# CONTROLSS_G2_EPWM11_CONTROLSS_G2_EPWM11 register map
Vendor: Texas Instruments
Peripheral module from a debugger description file (folder AM263).
Registers are 16-bit, read-write, reset values left out (the file's numbers can be read two ways) unless marked. A register's access mark holds for its fields unless they carry their own. Offsets are as the file gives them; lines under a group give offsets from that group; [hi:lo] are bit positions; {n}, {i} and the like mark numbered series; 'fields as' and 'values as' point back to an identical list; <NAME> marks a mode.

## CONTROLSS_G2_EPWM11_CONTROLSS_G2_EPWM11 (part 1 of 4)
0x12A CONTROLSS_G2_EPWM11_TZOSTFLG ro
  [15:0] DCCAP — Digital Compare Time-Base Counter Capture To enable time-base counter capture, set the DCCAPCLT[CAPE] bit to 1. If enabled, reflects the value of the time-base counter (TBCTR) on the low to high edge transition of a filtered (DCEVTFLT) event. Further capture events are ignored until the next period or zero as selected by the DCFCTL[PULSESEL] bit. Shadowing of DCCAP is enabled and disabled by the DCCAPCTL[SHDWMODE] bit. By default this register is shadowed. - If DCCAPCTL[SHDWMODE] = 0, then the shadow is enabled. In this mode, the active register is copied to the shadow register on the TBCTR = TBPRD or TBCTR = zero as defined by the DCFCTL[PULSESEL] bit. CPU reads of this register will return the shadow register value. - If DCCAPCTL[SHDWMODE] = 1, then the shadow register is disabled. In this mode, CPU reads will return the active register value. The active and shadow registers share the same memory map address.
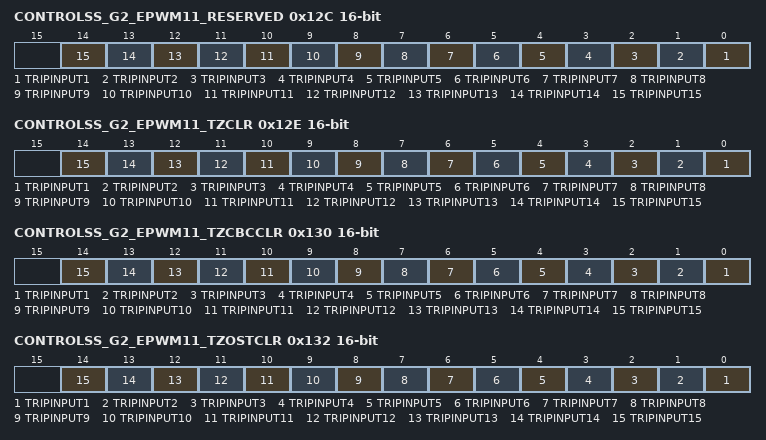
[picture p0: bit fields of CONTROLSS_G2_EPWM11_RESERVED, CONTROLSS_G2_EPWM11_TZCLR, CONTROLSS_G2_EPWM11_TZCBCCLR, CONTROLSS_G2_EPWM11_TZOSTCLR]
0x12C CONTROLSS_G2_EPWM11_RESERVED
  [n-1] TRIPINPUT{n} (n=1..15) — TRIP Input {n} 0: Trip Input {n} not selected as combinational ORed input 1: Trip Input {n} selected as combinational ORed input to DCAH mux
0x12E CONTROLSS_G2_EPWM11_TZCLR
  [n-1] TRIPINPUT{n} (n=1..15) — TRIP Input {n} 0: Trip Input {n} not selected as combinational ORed input 1: Trip Input {n} selected as combinational ORed input to DCAL mux
0x130 CONTROLSS_G2_EPWM11_TZCBCCLR
  [n-1] TRIPINPUT{n} (n=1..15) — TRIP Input {n} 0: Trip Input {n} not selected as combinational ORed input 1: Trip Input {n} selected as combinational ORed input to DCBH mux
0x132 CONTROLSS_G2_EPWM11_TZOSTCLR
  fields as CONTROLSS_G2_EPWM11_TZCLR
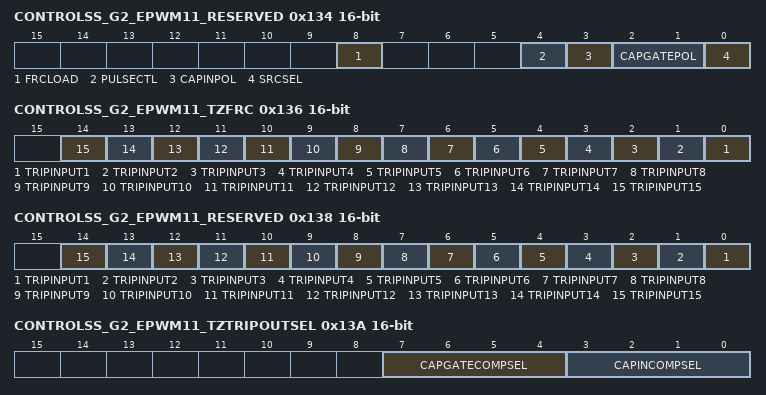
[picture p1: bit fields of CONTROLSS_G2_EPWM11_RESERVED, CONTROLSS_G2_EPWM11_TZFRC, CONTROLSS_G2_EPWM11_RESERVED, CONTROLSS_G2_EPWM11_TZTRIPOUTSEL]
0x134 CONTROLSS_G2_EPWM11_RESERVED access not given
  [8] FRCLOAD — 0: Writing of 0 is ignored. Always reads back a 0. 1: Forces a LOAD to occur on the DCCAP - an equivalent LOAD.active pulse (access RW RRETURNS0S)
  [4] PULSECTL rw — Capture Input Polarity Select Mux: 0: Pulse selection determined by PULSESEL bits (common pulse selection for Blanking and Capture logic) 1: Pulse selection determined by CAPMIXSEL register (independent pulse selection for Blaning and Capture logic)
  [3] CAPINPOL rw — Capture Input Polarity Select Mux: 0: CAPIN.sync not inverted 1: CAPIN.sync Inverted Default state assumption for these inputs can be active high. If the user is providing active low signal then invert option can be configured
  [2:1] CAPGATEPOL rw — Capture Gate Input Polarity Select Mux: 00: Set to 1 - Gate is always ON 01: Set to 0 - Gate is always OFF 10: CAPGATE.sync 11: CAPGATE.sync Inverted Default state assumption for these inputs can be active high. If the user is providing active low signal then invert option can be configured
  [0] SRCSEL rw — Capture Logic Input Select Mux: 0: DCEVTFILT (Sync) - same as Type-4 1: CAPIN.sync
0x136 CONTROLSS_G2_EPWM11_TZFRC
  [n-1] TRIPINPUT{n} (n=1..15) — TRIP Input {n} 0: Trip Input {n} not selected as combinational ORed input 1: Trip Input {n} selected as combinational ORed input to CAPGATE mux
0x138 CONTROLSS_G2_EPWM11_RESERVED
  [n-1] TRIPINPUT{n} (n=1..15) — TRIP Input {n} 0: Trip Input {n} not selected as combinational ORed input 1: Trip Input {n} selected as combinational ORed input to CAPIN mux
0x13A CONTROLSS_G2_EPWM11_TZTRIPOUTSEL
  [7:4] CAPGATECOMPSEL — Digital Compare A Low Input Select Bits 0000: TRIPIN1 0001: TRIPIN2 0010: TRIPIN3 0011: TRIPIN4 ... 1011: TRIPIN12 1100: Reserved 1101: TRIPIN14 1110: TRIPIN15 1111: Trip combination input (all trip inputs selected by CAPGATETRIPSEL register ORed together)
  [3:0] CAPINCOMPSEL — Digital Compare A High Input Select Bits 0000: TRIPIN1 0001: TRIPIN2 0010: TRIPIN3 0011: TRIPIN4 ... 1011: TRIPIN12 1100: Reserved 1101: TRIPIN14 1110: TRIPIN15 1111: Trip combination input (all trip inputs selected by CAPINTRIPSEL register ORed together)
0x13C CONTROLSS_G2_EPWM11_RESERVED
  [7:0] SPARE1_BITS — Not used in design currently
0x148 CONTROLSS_G2_EPWM11_ETSEL
  [7:0] SPARE2_BITS — Not used in design currently
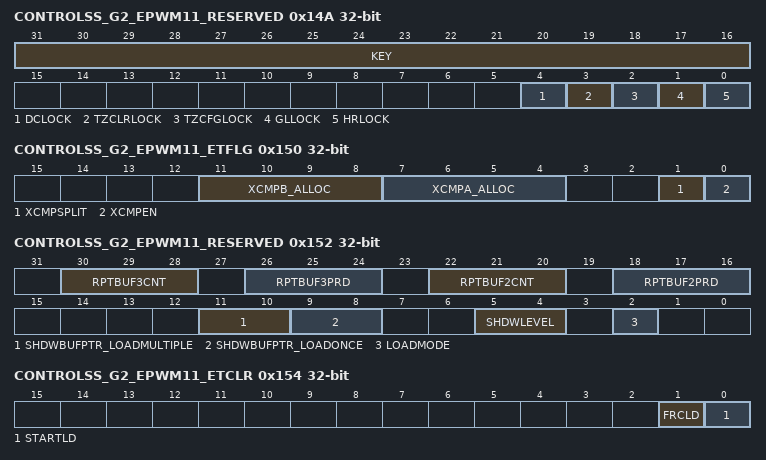
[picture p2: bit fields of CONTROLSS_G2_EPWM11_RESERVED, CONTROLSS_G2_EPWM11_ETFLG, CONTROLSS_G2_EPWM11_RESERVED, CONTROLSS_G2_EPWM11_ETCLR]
0x14A CONTROLSS_G2_EPWM11_RESERVED 32-bit access not given
  [31:16] KEY — Write to this register succeeds only if this field is written with a value of 0xa5a5 Note: [1] Due to this KEY, only 32-bit writes will succeed (provided the KEY matches). 16-bit writes to the upper or lower half of this register will be ignored (access RW RRETURNS0S)
  [4] DCLOCK — 0:Digital Compare registers from 0xC0 to 0xD9 offsets are protected by EALLOW. 1: Digital Compare registers from 0xC0 and 0xD9 offsets are locked and not writable. (access RWONCE WONCE)
  [3] TZCLRLOCK — 0:Digital Compare registers from 0x97 to 0x9B offsets are protected by EALLOW. 1: Digital Compare registers from 0x97 and 0x9B offsets are locked and not writable. (access RWONCE WONCE)
  [2] TZCFGLOCK — 0:TripZone registers from 0x80 to 0x8D and TZTRIPOUTSEL at 0x9D offsets are protected by EALLOW. 1: TripZone registers from 0x80 and 0x8D and TZTRIPOUTSEL at 0x9D offsets are locked and not writable. (access RWONCE WONCE)
  [1] GLLOCK — 0:TripZone registers from 0x34 to 0x35 offsets are protected by EALLOW. 1: TripZone registers from 0x34 to 0x35 offsets are locked and not writable (access RWONCE WONCE)
  [0] HRLOCK — 0: HRPWM registers from 0x20 to 0x2D offsets are protected by EALLOW 1: HRPWM registers from 0x20 and 0x2D offsets are locked and not writable. (access RWONCE WONCE)
0x14C CONTROLSS_G2_EPWM11_ETPS ro
  [15:0] HWVDELVAL — Hardware Valley Delay Value Register This read only register reflects the hardware delay value calculated by the equations defined in VCAPCTL[VDELAYDIV]. This reflects the latest value from the hardware calculations and can change every time valley capture sequence is triggered and VCAP1 and VCAP2 values are updated.
0x14E CONTROLSS_G2_EPWM11_RESERVED ro
  [15:0] VCNTVAL — Valley Time Base Counter Register This register reflects the captured VCNT value upon occurrence of STOPEDGE selected in VCNTCFG register.
0x150 CONTROLSS_G2_EPWM11_ETFLG 32-bit
  [11:8] XCMPB_ALLOC — XCMPn register allocation for CMPB: - 0 --' Reserved - 1 --' Reserved - 2 --' Reserved - 3 --' Reserved - 4 --' Reserved - 5 --' XCMP5 - 6 --' XCMP5, XCMP6 - 7 --' XCMP5, XCMP6, XCMP7 - 8 --' XCMP5, XCMP6, XCMP7, XCMP8 This register settings will take effect only when XCMPEN==1 And XCMPSPLIT ==1
  [7:4] XCMPA_ALLOC — XCMPn register allocation for CMPA: - 0 --' No XCMP - 1 --' XCMP1 - 2 --' XCMP1, XCMP2 - 3 --' XCMP1, XCMP2, XCMP3 - 4 --' XCMP1, XCMP2, XCMP3, XCMP4 - 5 --' XCMP1, XCMP2, XCMP3, XCMP4, XCMP5 - 6 --' XCMP1, XCMP2, XCMP3, XCMP4, XCMP5, XCMP6 - 7 --' XCMP1, XCMP2, XCMP3, XCMP4, XCMP5, XCMP6, XCMP7 - 8 --' XCMP1, XCMP2, XCMP3, XCMP4, XCMP5, XCMP6, XCMP7, XCMP8 This register settings will take effect only when XCMPEN==1 If XCMPSPLIT ==1, this field cannot be greater than 4. If XCMPSPLIT ==1 only lower 3 bits are used in this field.
  [1] XCMPSPLIT — XCMP Register Allocation Options: 0 : XCMP1-8 --' CMPA 1 : XCMP1-4 --'CMPA, XCMP5-8 ? CMPB This register settings will take effect only when XCMPEN==1
  [0] XCMPEN — XCMP Compare Register Operation Enable: 0 XCMP register operation Disabled (operation compatible to Type-4) 1 XCMP register operation Enabled (New CMPx registers are effective - section 1.3 details the operation)
0x152 CONTROLSS_G2_EPWM11_RESERVED 32-bit access per field
  [30:28] RPTBUF3CNT ro — Repeat Count Status Shadow Buffer 3: These bits indicate how many times shadow buffer 3 has been be applied before moving to the next buffer I,e, shadow buffer 1. 0,0,0 Shadow buffer reset value with STARTLD and copied to Active register 0,0,1 Shadow buffer applied twice on 2 successive load strobes 0,1,0 Shadow buffer applied thrice on 3 successive load strobes . . 1,1,1 Shadow buffer applied 8 times on 8 successive load strobes These bits reset to zero every time STARTLD is initiated. More details in section 1.3.3
  [26:24] RPTBUF3PRD rw — Repeat Count Shadow Buffer 3 : These bits indicate how many times shadow buffer 3 will be applied before moving to the next buffer I,e, shadow buffer 1. 0,0,0 Apply shadow buffer once and move to the next shadow buffer on the following load pulse 0,0,1 Apply shadow buffer twice on 2 successive load strobes and move to the next shadow buffer on the following load pulse 0,1,0 Apply shadow buffer thrice on 3 successive load strobes and move to the next shadow buffer on the following load pulse . . 1,1,1 Apply shadow buffer 8 times on 8 successive load strobes and move to the next shadow buffer on the following load pulse More details in section 1.3.3
  [22:20] RPTBUF2CNT ro — Repeat Count Status Shadow Buffer 2: These bits indicate how many times shadow buffer 2 has been be applied before moving to the next buffer I,e, shadow buffer 1. 0,0,0 Shadow buffer reset value with STARTLD and copied to Active register 0,0,1 Shadow buffer applied twice on 2 successive load strobes 0,1,0 Shadow buffer applied thrice on 3 successive load strobes . . 1,1,1 Shadow buffer applied 8 times on 8 successive load strobes These bits reset to zero every time STARTLD is initiated.
  [18:16] RPTBUF2PRD rw — Repeat Count Shadow Buffer 2 : These bits indicate how many times shadow buffer 2 will be applied before moving to the next buffer I,e, shadow buffer 1. 0,0,0 Apply shadow buffer once and move to the next shadow buffer on the following load pulse 0,0,1 Apply shadow buffer twice on 2 successive load strobes and move to the next shadow buffer on the following load pulse 0,1,0 Apply shadow buffer thrice on 3 successive load strobes and move to the next shadow buffer on the following load pulse . . 1,1,1 Apply shadow buffer 8 times on 8 successive load strobes and move to the next shadow buffer on the following load pulse More details in section 1.3.3
  [11:10] SHDWBUFPTR_LOADMULTIPLE ro — Register Load event count: These bits indicate the current shadow buffer in use. 0,0 Reset value 0,1 1 Shadow buffer 1 in use 1,0 2 Shadow buffer 2 in use 1,1 3 Shadow buffer 3 in use More details in section 1.3.3
  [9:8] SHDWBUFPTR_LOADONCE rw — Register Load event count: These bits indicate the current shadow buffer in use. 0,0 Reset value 0,1 1 Shadow buffer 1 in use 1,0 2 Shadow buffer 2 in use 1,1 3 Shadow buffer 3 in use More details in section 1.3.3
  [5:4] SHDWLEVEL rw — Shadow Register Level Allocation Options: These bits are effective only when XCMPEN is enabled. 0,0 : XXXX Shadow level is set at zero. XXXX Active register is available 0,1 : XXXX Shadow level is set at 1. XXXX_SHDW1 and Active registers are available 1,0 : XXXX Shadow level is set at 1. XXXX_SHDW1, XXXX_SHDW2 and Active registers are available 1,1 : XXXX Shadow level is set at 1. XXXX_SHDW1, XXXX_SHDW2, XXXX_SHDW3 and Active registers are available
  [2] LOADMODE rw — Load mode selection for Shadow registers: These bits are effective only when XCMPEN is enabled. 0 : (LOADONCE) Load occurs at every load strobe (CNT_Zero or FRCLD) from SHDWn? Active registers. And STARTLD is cleared after 1 load strobe. SHDWBUFPTR is not automatically decremented in this case. User would set the SHDWBUFPTR for subsequent loads. 1 : (LOADMULTIPLE) Load occurs at every load strobe (CNT_Zero or FRCLD) from SHDWn?Active registers. And STARTLD is cleared after SHDWLEVEL number of load strobes. SHDWBUFPTR decrements by 1 on a load strobe, until the SHDWBUFPTR reaches 1. More details in section 1.3.3
0x154 CONTROLSS_G2_EPWM11_ETCLR 32-bit access not given
  [1] FRCLD — Force reload event in one shot mode : Writing a 1 to this bit turn force one load event at the input of the event pre-scale counter as shown in the diagram below. This bit is intended to be used for testing and/or software force loading of the events in global load mode. Writing of 0 will be ignored. Always reads back a 0. (access RW RRETURNS0S)
  [0] STARTLD — Enable reload event : Writing a 1 to this bit turn the one shot latch condition ON. Upon occurrence of a chosen load strobe, one shadow to active reload occurs and the latch will be cleared. Hence writing '1' to this bit would allow load strobe event to pass through and block further strobe events. Writing of 0 will be ignored. Always reads back a 0. (access RW RRETURNS0S)
0x156 CONTROLSS_G2_EPWM11_RESERVED 32-bit
  [4:0] XLOADLINK — XLOAD Link Bits: Writes to the XLOAD registers in the ePWM module selected by the following bit selections results in a simultaneous write to the current ePWM module's XLOAD registers 00000: ePWM1 00001: ePWM2 00010: ePWM3 00011: ePWM4 00100: ePWM5 00101: ePWM6 00110: ePWM7 00111: ePWM8 01000: ePWM9 01001: ePWM10 01010: ePWM11 01011: ePWM12 01100: ePWM13 ... 11111: ePWM32
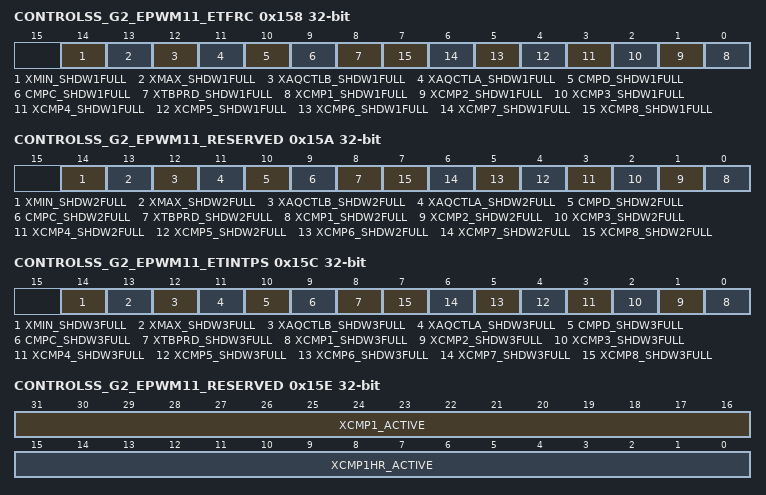
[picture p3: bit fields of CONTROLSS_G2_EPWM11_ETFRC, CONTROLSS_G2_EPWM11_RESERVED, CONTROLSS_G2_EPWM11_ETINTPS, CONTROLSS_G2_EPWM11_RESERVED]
0x158 CONTROLSS_G2_EPWM11_ETFRC 32-bit ro
  [14] XMIN_SHDW1FULL — 0 Shadow Register is not full yet 1 Indicates the Shadow Register is full, a CPU write will over-write current Shadow value
  [13] XMAX_SHDW1FULL — 0 Shadow Register is not full yet 1 Indicates the Shadow Register is full, a CPU write will over-write current Shadow value
  [12] XAQCTLB_SHDW1FULL — 0 Shadow Register is not full yet 1 Indicates the Shadow Register is full, a CPU write will over-write current Shadow value
  [11] XAQCTLA_SHDW1FULL — 0 Shadow Register is not full yet 1 Indicates the Shadow Register is full, a CPU write will over-write current Shadow value
  [10] CMPD_SHDW1FULL — 0 Shadow Register is not full yet 1 Indicates the Shadow Register is full, a CPU write will over-write current Shadow value
  [9] CMPC_SHDW1FULL — 0 Shadow Register is not full yet 1 Indicates the Shadow Register is full, a CPU write will over-write current Shadow value
  [8] XTBPRD_SHDW1FULL — 0 Shadow Register is not full yet 1 Indicates the Shadow Register is full, a CPU write will over-write current Shadow value
  [n-1] XCMP{n}_SHDW1FULL (n=1..8) — 0 Shadow Register is not full yet 1 Indicates the Shadow Register is full, a CPU write will over-write current Shadow value
0x15A CONTROLSS_G2_EPWM11_RESERVED 32-bit ro
  [14] XMIN_SHDW2FULL — 0 Shadow Register is not full yet 1 Indicates the Shadow Register is full, a CPU write will over-write current Shadow value
  [13] XMAX_SHDW2FULL — 0 Shadow Register is not full yet 1 Indicates the Shadow Register is full, a CPU write will over-write current Shadow value
  [12] XAQCTLB_SHDW2FULL — 0 Shadow Register is not full yet 1 Indicates the Shadow Register is full, a CPU write will over-write current Shadow value
  [11] XAQCTLA_SHDW2FULL — 0 Shadow Register is not full yet 1 Indicates the Shadow Register is full, a CPU write will over-write current Shadow value
  [10] CMPD_SHDW2FULL — 0 Shadow Register is not full yet 1 Indicates the Shadow Register is full, a CPU write will over-write current Shadow value
  [9] CMPC_SHDW2FULL — 0 Shadow Register is not full yet 1 Indicates the Shadow Register is full, a CPU write will over-write current Shadow value
  [8] XTBPRD_SHDW2FULL — 0 Shadow Register is not full yet 1 Indicates the Shadow Register is full, a CPU write will over-write current Shadow value
  [n-1] XCMP{n}_SHDW2FULL (n=1..8) — 0 Shadow Register is not full yet 1 Indicates the Shadow Register is full, a CPU write will over-write current Shadow value
0x15C CONTROLSS_G2_EPWM11_ETINTPS 32-bit ro
  [14] XMIN_SHDW3FULL — 0 Shadow Register is not full yet 1 Indicates the Shadow Register is full, a CPU write will over-write current Shadow value
  [13] XMAX_SHDW3FULL — 0 Shadow Register is not full yet 1 Indicates the Shadow Register is full, a CPU write will over-write current Shadow value
  [12] XAQCTLB_SHDW3FULL — 0 Shadow Register is not full yet 1 Indicates the Shadow Register is full, a CPU write will over-write current Shadow value
  [11] XAQCTLA_SHDW3FULL — 0 Shadow Register is not full yet 1 Indicates the Shadow Register is full, a CPU write will over-write current Shadow value
  [10] CMPD_SHDW3FULL — 0 Shadow Register is not full yet 1 Indicates the Shadow Register is full, a CPU write will over-write current Shadow value
  [9] CMPC_SHDW3FULL — 0 Shadow Register is not full yet 1 Indicates the Shadow Register is full, a CPU write will over-write current Shadow value
  [8] XTBPRD_SHDW3FULL — 0 Shadow Register is not full yet 1 Indicates the Shadow Register is full, a CPU write will over-write current Shadow value
  [n-1] XCMP{n}_SHDW3FULL (n=1..8) — 0 Shadow Register is not full yet 1 Indicates the Shadow Register is full, a CPU write will over-write current Shadow value
0x15E CONTROLSS_G2_EPWM11_RESERVED 32-bit
  [31:16] XCMP1_ACTIVE — XCMP1_ACTIVE Register The value in the XCMP1_ACTIVE register is loaded into CMPA/B (shadow/active) registers when shadow to active load occurs.
  [15:0] XCMP1HR_ACTIVE — XCMP1HR_ACTIVE Register The value in the XCMP1HR_ACTIVE register is loaded into CMPA/BHR (shadow/active) registers when shadow to active load occurs.
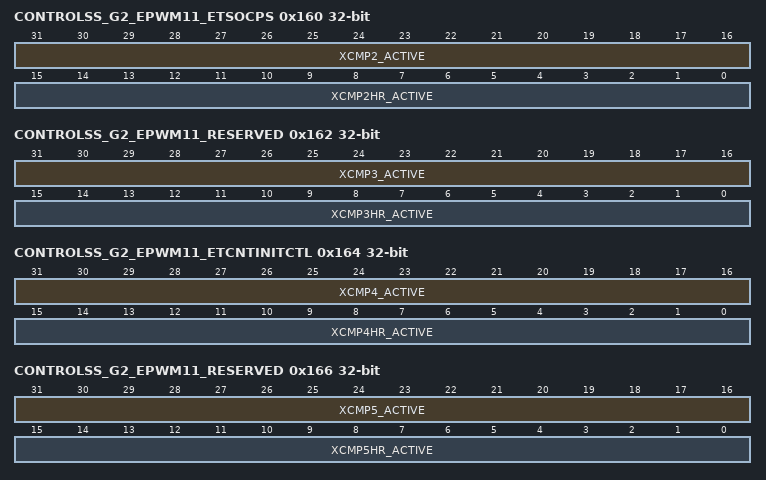
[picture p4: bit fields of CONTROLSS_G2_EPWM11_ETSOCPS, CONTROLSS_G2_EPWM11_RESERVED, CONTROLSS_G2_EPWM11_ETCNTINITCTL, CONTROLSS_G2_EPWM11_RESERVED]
0x160 CONTROLSS_G2_EPWM11_ETSOCPS 32-bit
  [31:16] XCMP2_ACTIVE — XCMP2_ACTIVE Register The value in the XCMP2_ACTIVE register is loaded into CMPA/B (shadow/active) registers when shadow to active load occurs.
  [15:0] XCMP2HR_ACTIVE — XCMP2HR_ACTIVE Register The value in the XCMP2HR_ACTIVE register is loaded into CMPA/BHR (shadow/active) registers when shadow to active load occurs.
0x162 CONTROLSS_G2_EPWM11_RESERVED 32-bit
  [31:16] XCMP3_ACTIVE — XCMP3_ACTIVE Register The value in the XCMP3_ACTIVE register is loaded into CMPA/B (shadow/active) registers when shadow to active load occurs.
  [15:0] XCMP3HR_ACTIVE — XCMP3HR_ACTIVE Register The value in the XCMP3HR_ACTIVE register is loaded into CMPA/BHR (shadow/active) registers when shadow to active load occurs.
0x164 CONTROLSS_G2_EPWM11_ETCNTINITCTL 32-bit
  [31:16] XCMP4_ACTIVE — XCMP4_ACTIVE Register The value in the XCMP4_ACTIVE register is loaded into CMPA/B (shadow/active) registers when shadow to active load occurs.
  [15:0] XCMP4HR_ACTIVE — XCMP4HR_ACTIVE Register The value in the XCMP4HR_ACTIVE register is loaded into CMPA/BHR (shadow/active) registers when shadow to active load occurs.
0x166 CONTROLSS_G2_EPWM11_RESERVED 32-bit
  [31:16] XCMP5_ACTIVE — XCMP5_ACTIVE Register The value in the XCMP5_ACTIVE register is loaded into CMPA/B (shadow/active) registers when shadow to active load occurs.
  [15:0] XCMP5HR_ACTIVE — XCMP5HR_ACTIVE Register The value in the XCMP5HR_ACTIVE register is loaded into CMPA/BHR (shadow/active) registers when shadow to active load occurs.
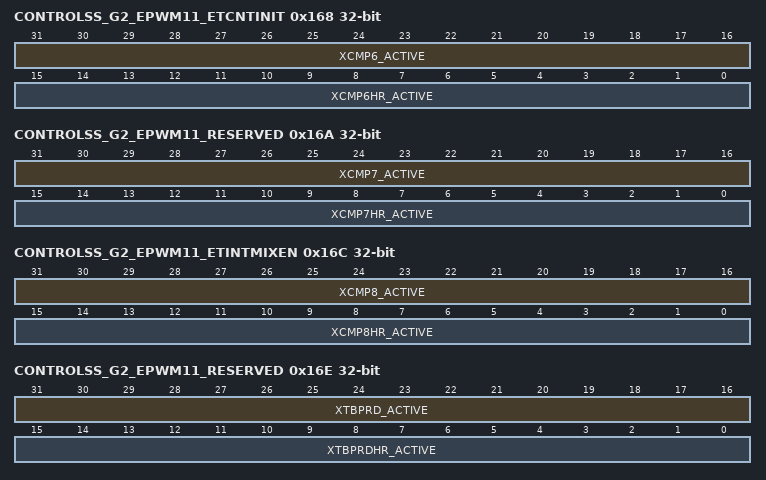
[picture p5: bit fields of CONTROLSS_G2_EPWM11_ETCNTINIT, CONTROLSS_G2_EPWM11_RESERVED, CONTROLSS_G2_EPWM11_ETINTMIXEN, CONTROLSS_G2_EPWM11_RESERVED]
0x168 CONTROLSS_G2_EPWM11_ETCNTINIT 32-bit
  [31:16] XCMP6_ACTIVE — XCMP6_ACTIVE Register The value in the XCMP6_ACTIVE register is loaded into CMPA/B (shadow/active) registers when shadow to active load occurs.
  [15:0] XCMP6HR_ACTIVE — XCMP6HR_ACTIVE Register The value in the XCMP6HR_ACTIVE register is loaded into CMPA/BHR (shadow/active) registers when shadow to active load occurs.
0x16A CONTROLSS_G2_EPWM11_RESERVED 32-bit
  [31:16] XCMP7_ACTIVE — XCMP7_ACTIVE Register The value in the XCMP7_ACTIVE register is loaded into CMPA/B (shadow/active) registers when shadow to active load occurs.
  [15:0] XCMP7HR_ACTIVE — XCMP7HR_ACTIVE Register The value in the XCMP7HR_ACTIVE register is loaded into CMPA/BHR (shadow/active) registers when shadow to active load occurs.
0x16C CONTROLSS_G2_EPWM11_ETINTMIXEN 32-bit
  [31:16] XCMP8_ACTIVE — XCMP8_ACTIVE Register The value in the XCMP8_ACTIVE register is loaded into CMPA/B (shadow/active) registers when shadow to active load occurs.
  [15:0] XCMP8HR_ACTIVE — XCMP8HR_ACTIVE Register The value in the XCMP8HR_ACTIVE register is loaded into CMPA/BHR (shadow/active) registers when shadow to active load occurs.
0x16E CONTROLSS_G2_EPWM11_RESERVED 32-bit
  [31:16] XTBPRD_ACTIVE — The value in the XTBPRD_ACTIVE register is loaded into TBPRD (shadow/active) registers when shadow to active load occurs.
  [15:0] XTBPRDHR_ACTIVE — The value in the XTBPRDHR_ACTIVE register is loaded into TBPRDHR (shadow/active) registers when shadow to active load occurs.
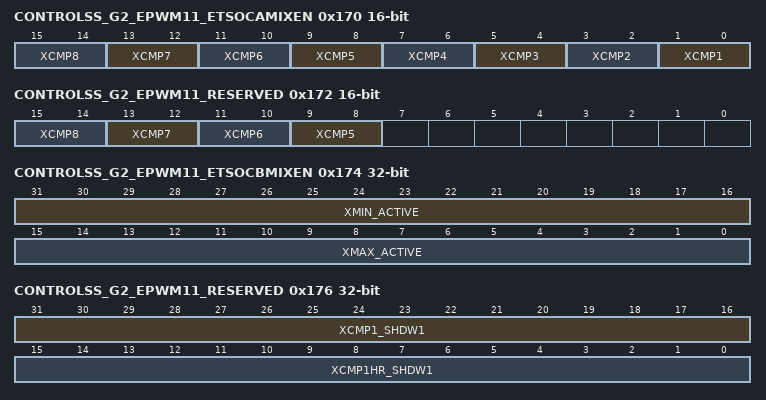
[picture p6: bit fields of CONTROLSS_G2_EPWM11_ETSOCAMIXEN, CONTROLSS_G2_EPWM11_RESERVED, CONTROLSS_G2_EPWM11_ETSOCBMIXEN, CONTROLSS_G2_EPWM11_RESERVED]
0x170 CONTROLSS_G2_EPWM11_ETSOCAMIXEN
  [2n-1:2n-2] XCMP{n} (n=1..8) — Action when Counter = CMP{n} 0,0 Do nothing (action disabled) 0,1 Clear (low) 1,0 Set (high) 1,1 Toggle (Low -' High, High -' Low)
0x172 CONTROLSS_G2_EPWM11_RESERVED
  [2n-1:2n-2] XCMP{n} (n=5..8) — Action when Counter = CMP{n} 0,0 Do nothing (action disabled) 0,1 Clear (low) 1,0 Set (high) 1,1 Toggle (Low -' High, High -' Low)
0x174 CONTROLSS_G2_EPWM11_ETSOCBMIXEN 32-bit
  [31:16] XMIN_ACTIVE — The value in the XMIN_ACTIVE register is used for comparision against the threshold of the capture counter at any given time.
  [15:0] XMAX_ACTIVE — The value in the XMAX_ACTIVE register is used for comparision against the threshold of the capture counter at any given time.
0x176 CONTROLSS_G2_EPWM11_RESERVED 32-bit
  [31:16] XCMP1_SHDW1 — XCMP1_SHDW1 Register The value in the XCMP1_SHDW1 register is loaded into XCMP1_ACTIVE register when shadow to active load occurs.
  [15:0] XCMP1HR_SHDW1 — XCMP1HR_SHDW1 Register The value in the XCMP1HR_SHDW1 register is loaded into XCMP1HR_ACTIVE register when shadow to active load occurs.
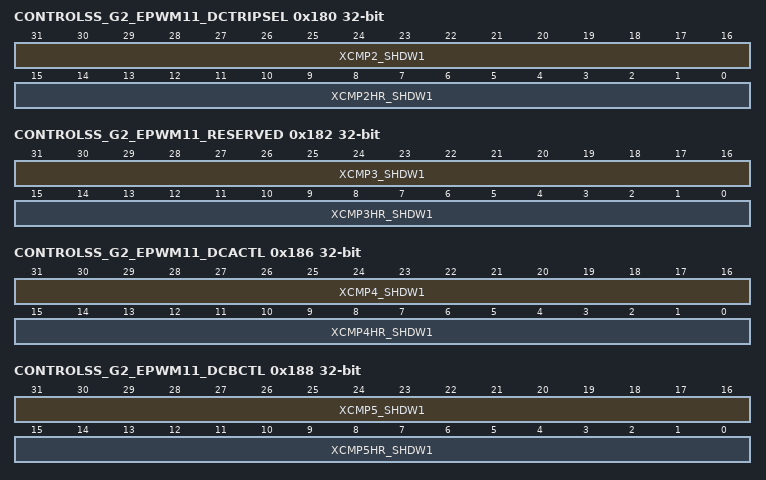
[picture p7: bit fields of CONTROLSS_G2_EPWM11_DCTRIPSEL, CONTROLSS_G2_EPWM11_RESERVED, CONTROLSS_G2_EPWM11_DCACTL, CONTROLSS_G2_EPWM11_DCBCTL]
0x180 CONTROLSS_G2_EPWM11_DCTRIPSEL 32-bit
  [31:16] XCMP2_SHDW1 — XCMP2_SHDW1 Register The value in the XCMP2_SHDW1 register is loaded into XCMP2_ACTIVE register when shadow to active load occurs.
  [15:0] XCMP2HR_SHDW1 — XCMP2HR_SHDW1 Register The value in the XCMP2HR_SHDW1 register is loaded into XCMP2HR_ACTIVE register when shadow to active load occurs.
0x182 CONTROLSS_G2_EPWM11_RESERVED 32-bit
  [31:16] XCMP3_SHDW1 — XCMP3_SHDW1 Register The value in the XCMP3_SHDW1 register is loaded into XCMP3_ACTIVE register when shadow to active load occurs.
  [15:0] XCMP3HR_SHDW1 — XCMP3HR_SHDW1 Register The value in the XCMP3HR_SHDW1 register is loaded into XCMP3HR_ACTIVE register when shadow to active load occurs.
0x186 CONTROLSS_G2_EPWM11_DCACTL 32-bit
  [31:16] XCMP4_SHDW1 — XCMP4_SHDW1 Register The value in the XCMP4_SHDW1 register is loaded into XCMP4_ACTIVE register when shadow to active load occurs.
  [15:0] XCMP4HR_SHDW1 — XCMP4HR_SHDW1 Register The value in the XCMP4HR_SHDW1 register is loaded into XCMP4HR_ACTIVE register when shadow to active load occurs.
0x188 CONTROLSS_G2_EPWM11_DCBCTL 32-bit
  [31:16] XCMP5_SHDW1 — XCMP5_SHDW1 Register The value in the XCMP5_SHDW1 register is loaded into XCMP5_ACTIVE register when shadow to active load occurs.
  [15:0] XCMP5HR_SHDW1 — XCMP5HR_SHDW1 Register The value in the XCMP5HR_SHDW1 register is loaded into XCMP5HR_ACTIVE register when shadow to active load occurs.
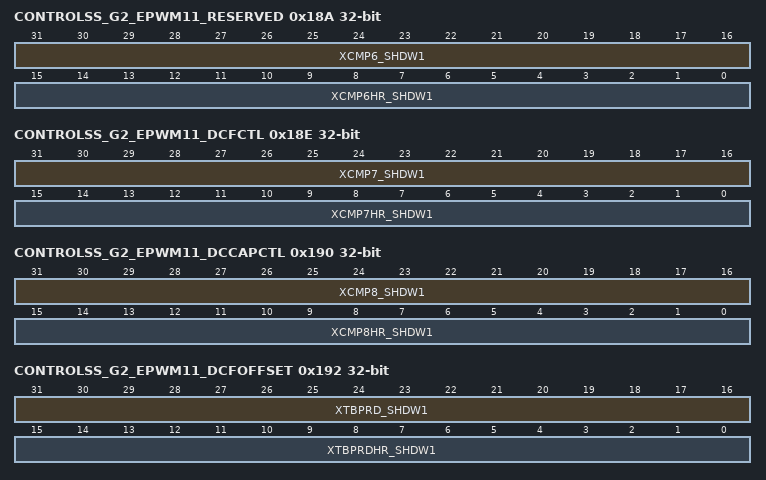
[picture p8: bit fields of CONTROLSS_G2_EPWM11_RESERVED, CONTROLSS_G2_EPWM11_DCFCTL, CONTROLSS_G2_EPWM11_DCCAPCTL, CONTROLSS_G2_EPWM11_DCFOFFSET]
0x18A CONTROLSS_G2_EPWM11_RESERVED 32-bit
  [31:16] XCMP6_SHDW1 — XCMP6_SHDW1 Register The value in the XCMP6_SHDW1 register is loaded into XCMP6_ACTIVE register when shadow to active load occurs.
  [15:0] XCMP6HR_SHDW1 — XCMP6HR_SHDW1 Register The value in the XCMP6HR_SHDW1 register is loaded into XCMP6HR_ACTIVE register when shadow to active load occurs.
0x18E CONTROLSS_G2_EPWM11_DCFCTL 32-bit
  [31:16] XCMP7_SHDW1 — XCMP7_SHDW1 Register The value in the XCMP7_SHDW1 register is loaded into XCMP7_ACTIVE register when shadow to active load occurs.
  [15:0] XCMP7HR_SHDW1 — XCMP7HR_SHDW1 Register The value in the XCMP7HR_SHDW1 register is loaded into XCMP7HR_ACTIVE register when shadow to active load occurs.
0x190 CONTROLSS_G2_EPWM11_DCCAPCTL 32-bit
  [31:16] XCMP8_SHDW1 — XCMP8_SHDW1 Register The value in the XCMP8_SHDW1 register is loaded into XCMP8_ACTIVE register when shadow to active load occurs.
  [15:0] XCMP8HR_SHDW1 — XCMP8HR_SHDW1 Register The value in the XCMP8HR_SHDW1 register is loaded into XCMP8HR_ACTIVE register when shadow to active load occurs.
0x192 CONTROLSS_G2_EPWM11_DCFOFFSET 32-bit
  [31:16] XTBPRD_SHDW1 — The value in the XTBPRD_SHDW1 register is loaded into XTBPRD_ ACTIVE register when shadow to active load occurs.
  [15:0] XTBPRDHR_SHDW1 — The value in the XTBPRDHR_SHDW1 register is loaded into XTBPRDHR_ACTIVE register when shadow to active load occurs.
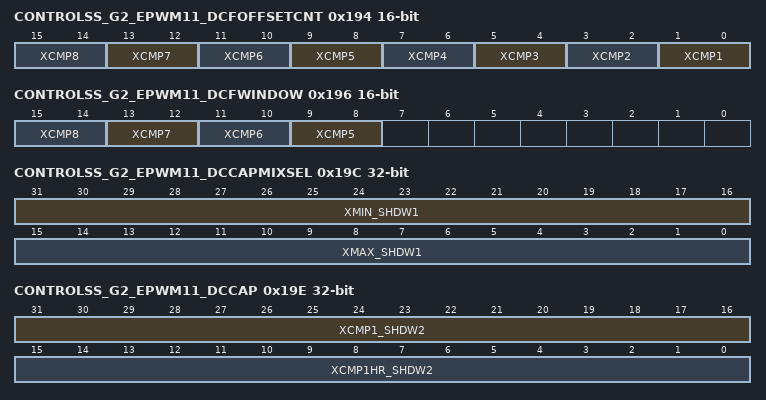
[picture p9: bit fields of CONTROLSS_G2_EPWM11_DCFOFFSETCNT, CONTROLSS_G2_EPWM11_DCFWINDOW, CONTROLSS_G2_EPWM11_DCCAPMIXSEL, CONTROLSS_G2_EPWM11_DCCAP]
0x194 CONTROLSS_G2_EPWM11_DCFOFFSETCNT
  fields as CONTROLSS_G2_EPWM11_ETSOCAMIXEN
0x196 CONTROLSS_G2_EPWM11_DCFWINDOW
  [2n-1:2n-2] XCMP{n} (n=5..8) — Action when Counter = CMP{n} 0,0 Do nothing (action disabled) 0,1 Clear (low) 1,0 Set (high) 1,1 Toggle (Low -' High, High -' Low)
0x198 CONTROLSS_G2_EPWM11_DCFWINDOWCNT
  [15:0] CMPC_SHDW1 — The value in the CMPC_SHDW1 register is loaded into CMPC_ACTIVE register when shadow to active load occurs.
0x19A CONTROLSS_G2_EPWM11_BLANKPULSEMIXSEL
  [15:0] CMPD_SHDW1 — The value in the CMPD_SHDW1 register is loaded into CMPD_ACTIVE register when shadow to active load occurs.
0x19C CONTROLSS_G2_EPWM11_DCCAPMIXSEL 32-bit
  [31:16] XMIN_SHDW1 — The value in the XMIN_SHDW1 register is loaded into XMIN_ACTIVE register when shadow to active load occurs.
  [15:0] XMAX_SHDW1 — The value in the XMAX_SHDW1 register is loaded into XMAX_ACTIVE register when shadow to active load occurs.
0x19E CONTROLSS_G2_EPWM11_DCCAP 32-bit
  [31:16] XCMP1_SHDW2 — XCMP1_SHDW2 Register The value in the XCMP1_SHDW2 register is loaded into XCMP1_ACTIVE register when shadow to active load occurs.
  [15:0] XCMP1HR_SHDW2 — XCMP1HR_SHDW2 Register The value in the XCMP1HR_SHDW2 register is loaded into XCMP1HR_ACTIVE register when shadow to active load occurs.
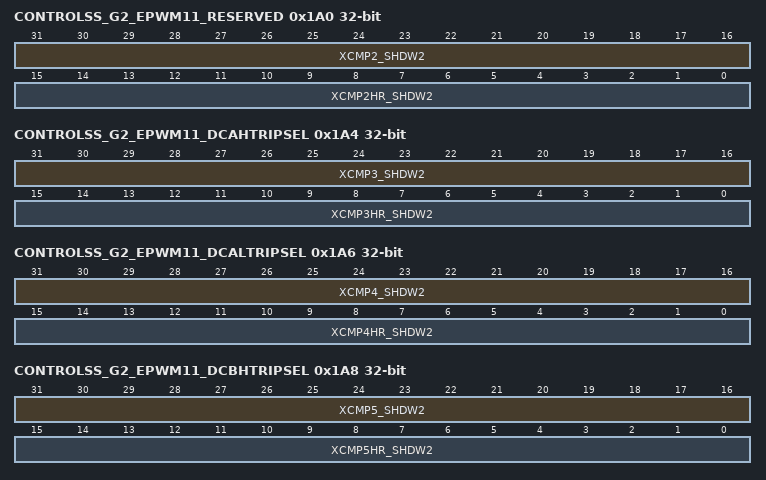
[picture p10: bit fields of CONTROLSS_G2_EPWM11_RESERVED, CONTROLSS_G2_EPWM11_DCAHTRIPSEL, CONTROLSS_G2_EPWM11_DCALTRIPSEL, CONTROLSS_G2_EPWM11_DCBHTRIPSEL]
0x1A0 CONTROLSS_G2_EPWM11_RESERVED 32-bit
  [31:16] XCMP2_SHDW2 — XCMP2_SHDW2 Register The value in the XCMP2_SHDW2 register is loaded into XCMP2_ACTIVE register when shadow to active load occurs.
  [15:0] XCMP2HR_SHDW2 — XCMP2HR_SHDW2 Register The value in the XCMP2HR_SHDW2 register is loaded into XCMP2HR_ACTIVE register when shadow to active load occurs.
0x1A4 CONTROLSS_G2_EPWM11_DCAHTRIPSEL 32-bit
  [31:16] XCMP3_SHDW2 — XCMP3_SHDW2 Register The value in the XCMP3_SHDW2 register is loaded into XCMP3_ACTIVE register when shadow to active load occurs.
  [15:0] XCMP3HR_SHDW2 — XCMP3HR_SHDW2 Register The value in the XCMP3HR_SHDW2 register is loaded into XCMP3HR_ACTIVE register when shadow to active load occurs.
0x1A6 CONTROLSS_G2_EPWM11_DCALTRIPSEL 32-bit
  [31:16] XCMP4_SHDW2 — XCMP4_SHDW2 Register The value in the XCMP4_SHDW2 register is loaded into XCMP4_ACTIVE register when shadow to active load occurs.
  [15:0] XCMP4HR_SHDW2 — XCMP4HR_SHDW2 Register The value in the XCMP4HR_SHDW2 register is loaded into XCMP4HR_ACTIVE register when shadow to active load occurs.
0x1A8 CONTROLSS_G2_EPWM11_DCBHTRIPSEL 32-bit
  [31:16] XCMP5_SHDW2 — XCMP5_SHDW2 Register The value in the XCMP5_SHDW2 register is loaded into XCMP5_ACTIVE register when shadow to active load occurs.
  [15:0] XCMP5HR_SHDW2 — XCMP5HR_SHDW2 Register The value in the XCMP5HR_SHDW2 register is loaded into XCMP5HR_ACTIVE register when shadow to active load occurs.
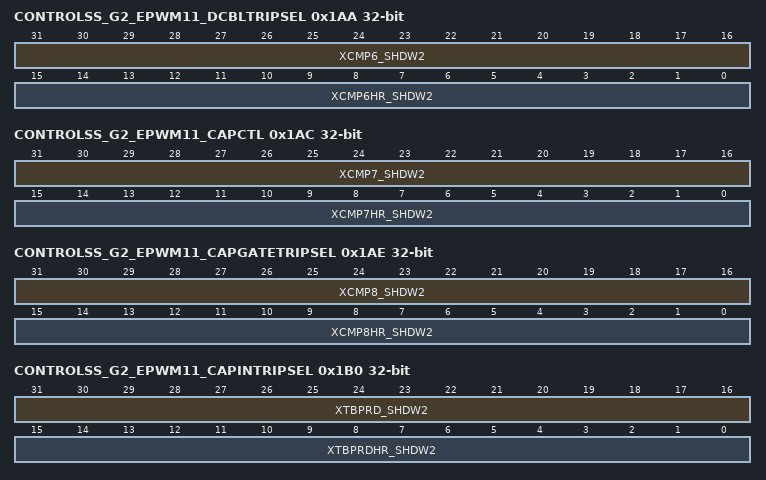
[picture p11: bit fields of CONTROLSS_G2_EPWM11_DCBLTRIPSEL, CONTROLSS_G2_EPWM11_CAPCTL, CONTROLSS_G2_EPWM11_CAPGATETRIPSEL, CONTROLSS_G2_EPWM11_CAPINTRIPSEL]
0x1AA CONTROLSS_G2_EPWM11_DCBLTRIPSEL 32-bit
  [31:16] XCMP6_SHDW2 — XCMP6_SHDW2 Register The value in the XCMP6_SHDW2 register is loaded into XCMP6_ACTIVE register when shadow to active load occurs.
  [15:0] XCMP6HR_SHDW2 — XCMP6HR_SHDW2 Register The value in the XCMP6HR_SHDW2 register is loaded into XCMP6HR_ACTIVE register when shadow to active load occurs.
0x1AC CONTROLSS_G2_EPWM11_CAPCTL 32-bit
  [31:16] XCMP7_SHDW2 — XCMP7_SHDW2 Register The value in the XCMP7_SHDW2 register is loaded into XCMP7_ACTIVE register when shadow to active load occurs.
  [15:0] XCMP7HR_SHDW2 — XCMP7HR_SHDW2 Register The value in the XCMP7HR_SHDW2 register is loaded into XCMP7HR_ACTIVE register when shadow to active load occurs.
0x1AE CONTROLSS_G2_EPWM11_CAPGATETRIPSEL 32-bit
  [31:16] XCMP8_SHDW2 — XCMP8_SHDW2 Register The value in the XCMP8_SHDW2 register is loaded into XCMP8_ACTIVE register when shadow to active load occurs.
  [15:0] XCMP8HR_SHDW2 — XCMP8HR_SHDW2 Register The value in the XCMP8HR_SHDW2 register is loaded into XCMP8HR_ACTIVE register when shadow to active load occurs.
0x1B0 CONTROLSS_G2_EPWM11_CAPINTRIPSEL 32-bit
  [31:16] XTBPRD_SHDW2 — The value in the XTBPRD_SHDW2 register is loaded into XTBPRD_ ACTIVE register when shadow to active load occurs.
  [15:0] XTBPRDHR_SHDW2 — The value in the XTBPRDHR_SHDW2 register is loaded into XTBPRDHR_ACTIVE register when shadow to active load occurs.
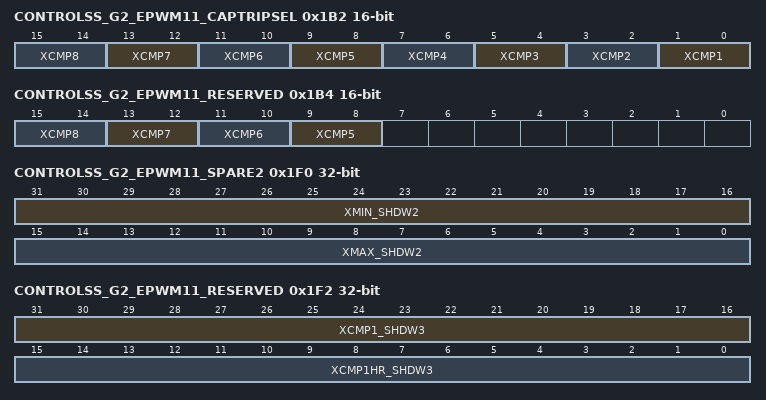
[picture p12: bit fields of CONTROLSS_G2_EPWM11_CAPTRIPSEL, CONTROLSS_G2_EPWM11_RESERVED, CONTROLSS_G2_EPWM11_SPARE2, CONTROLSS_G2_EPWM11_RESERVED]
0x1B2 CONTROLSS_G2_EPWM11_CAPTRIPSEL
  fields as CONTROLSS_G2_EPWM11_ETSOCAMIXEN
0x1B4 CONTROLSS_G2_EPWM11_RESERVED
  fields as CONTROLSS_G2_EPWM11_DCFWINDOW
0x1EC CONTROLSS_G2_EPWM11_SPARE1
  [15:0] CMPC_SHDW2 — The value in the CMPC_SHDW2 register is loaded into CMPC_ACTIVE register when shadow to active load occurs.
0x1EE CONTROLSS_G2_EPWM11_RESERVED
  [15:0] CMPD_SHDW2 — The value in the CMPD_SHDW2 register is loaded into CMPD_ACTIVE register when shadow to active load occurs.
0x1F0 CONTROLSS_G2_EPWM11_SPARE2 32-bit
  [31:16] XMIN_SHDW2 — The value in the XMIN_SHDW2 register is loaded into XMIN_ACTIVE register when shadow to active load occurs.
  [15:0] XMAX_SHDW2 — The value in the XMAX_SHDW2 register is loaded into XMAX_ACTIVE register when shadow to active load occurs.
0x1F2 CONTROLSS_G2_EPWM11_RESERVED 32-bit
  [31:16] XCMP1_SHDW3 — XCMP1_SHDW3 Register The value in the XCMP1_SHDW3 register is loaded into XCMP1_ACTIVE register when shadow to active load occurs.
  [15:0] XCMP1HR_SHDW3 — XCMP1HR_SHDW3 Register The value in the XCMP1HR_SHDW3 register is loaded into XCMP1HR_ACTIVE register when shadow to active load occurs.
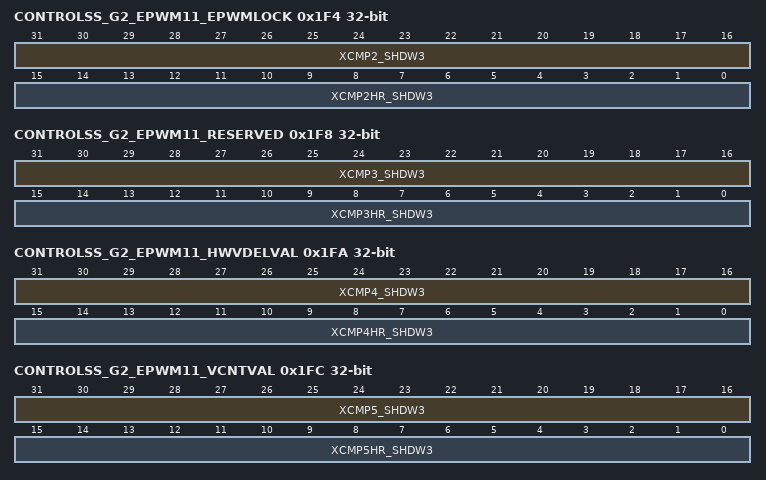
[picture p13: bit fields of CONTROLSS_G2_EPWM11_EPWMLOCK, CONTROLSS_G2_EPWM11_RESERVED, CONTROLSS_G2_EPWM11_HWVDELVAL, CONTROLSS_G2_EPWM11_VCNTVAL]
0x1F4 CONTROLSS_G2_EPWM11_EPWMLOCK 32-bit
  [31:16] XCMP2_SHDW3 — XCMP2_SHDW3 Register The value in the XCMP2_SHDW3 register is loaded into XCMP2_ACTIVE register when shadow to active load occurs.
  [15:0] XCMP2HR_SHDW3 — XCMP2HR_SHDW3 Register The value in the XCMP2HR_SHDW3 register is loaded into XCMP2HR_ACTIVE register when shadow to active load occurs.
0x1F8 CONTROLSS_G2_EPWM11_RESERVED 32-bit
  [31:16] XCMP3_SHDW3 — XCMP3_SHDW3 Register The value in the XCMP3_SHDW3 register is loaded into XCMP3_ACTIVE register when shadow to active load occurs.
  [15:0] XCMP3HR_SHDW3 — XCMP3HR_SHDW3 Register The value in the XCMP3HR_SHDW3 register is loaded into XCMP3HR_ACTIVE register when shadow to active load occurs.
0x1FA CONTROLSS_G2_EPWM11_HWVDELVAL 32-bit
  [31:16] XCMP4_SHDW3 — XCMP4_SHDW3 Register The value in the XCMP4_SHDW3 register is loaded into XCMP4_ACTIVE register when shadow to active load occurs.
  [15:0] XCMP4HR_SHDW3 — XCMP4HR_SHDW3 Register The value in the XCMP4HR_SHDW3 register is loaded into XCMP4HR_ACTIVE register when shadow to active load occurs.
0x1FC CONTROLSS_G2_EPWM11_VCNTVAL 32-bit
  [31:16] XCMP5_SHDW3 — XCMP5_SHDW3 Register The value in the XCMP5_SHDW3 register is loaded into XCMP5_ACTIVE register when shadow to active load occurs.
  [15:0] XCMP5HR_SHDW3 — XCMP5HR_SHDW3 Register The value in the XCMP5HR_SHDW3 register is loaded into XCMP5HR_ACTIVE register when shadow to active load occurs.
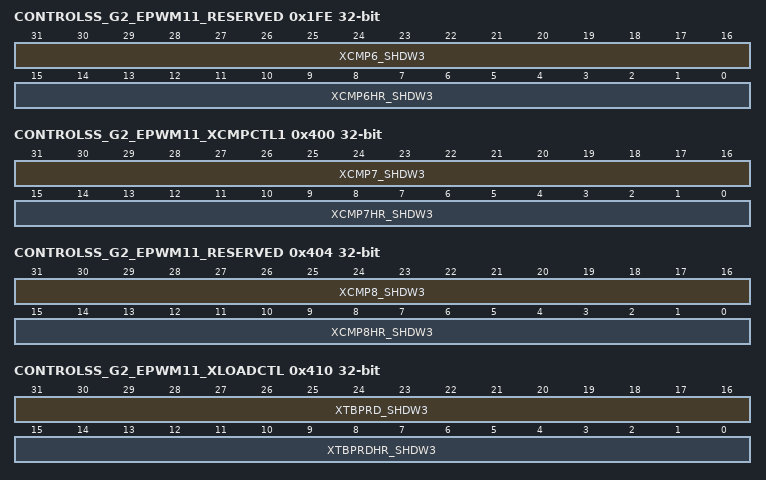
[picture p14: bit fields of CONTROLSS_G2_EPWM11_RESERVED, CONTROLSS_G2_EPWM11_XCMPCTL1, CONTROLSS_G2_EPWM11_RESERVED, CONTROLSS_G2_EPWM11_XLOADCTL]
0x1FE CONTROLSS_G2_EPWM11_RESERVED 32-bit
  [31:16] XCMP6_SHDW3 — XCMP6_SHDW3 Register The value in the XCMP6_SHDW3 register is loaded into XCMP6_ACTIVE register when shadow to active load occurs.
  [15:0] XCMP6HR_SHDW3 — XCMP6HR_SHDW3 Register The value in the XCMP6HR_SHDW3 register is loaded into XCMP6HR_ACTIVE register when shadow to active load occurs.
0x400 CONTROLSS_G2_EPWM11_XCMPCTL1 32-bit
  [31:16] XCMP7_SHDW3 — XCMP7_SHDW3 Register The value in the XCMP7_SHDW3 register is loaded into XCMP7_ACTIVE register when shadow to active load occurs.
  [15:0] XCMP7HR_SHDW3 — XCMP7HR_SHDW3 Register The value in the XCMP7HR_SHDW3 register is loaded into XCMP7HR_ACTIVE register when shadow to active load occurs.
0x404 CONTROLSS_G2_EPWM11_RESERVED 32-bit
  [31:16] XCMP8_SHDW3 — XCMP8_SHDW3 Register The value in the XCMP8_SHDW3 register is loaded into XCMP8_ACTIVE register when shadow to active load occurs.
  [15:0] XCMP8HR_SHDW3 — XCMP8HR_SHDW3 Register The value in the XCMP8HR_SHDW3 register is loaded into XCMP8HR_ACTIVE register when shadow to active load occurs.
0x410 CONTROLSS_G2_EPWM11_XLOADCTL 32-bit
  [31:16] XTBPRD_SHDW3 — The value in the XTBPRD_SHDW3 register is loaded into XTBPRD_ ACTIVE register when shadow to active load occurs.
  [15:0] XTBPRDHR_SHDW3 — The value in the XTBPRDHR_SHDW3 register is loaded into XTBPRDHR_ACTIVE register when shadow to active load occurs.
0x414 CONTROLSS_G2_EPWM11_RESERVED
  fields as CONTROLSS_G2_EPWM11_ETSOCAMIXEN
0x418 CONTROLSS_G2_EPWM11_XLOAD
  fields as CONTROLSS_G2_EPWM11_DCFWINDOW
0x41C CONTROLSS_G2_EPWM11_EPWMXLINKXLOAD
  [15:0] CMPC_SHDW3 — The value in the CMPC_SHDW3 register is loaded into CMPC_ACTIVE register when shadow to active load occurs.
0x420 CONTROLSS_G2_EPWM11_XREGSHDW1STS
  [15:0] CMPD_SHDW3 — The value in the CMPD_SHDW3 register is loaded into CMPD_ACTIVE register when shadow to active load occurs.
0x424 CONTROLSS_G2_EPWM11_RESERVED 32-bit
  [31:16] XMIN_SHDW3 — The value in the XMIN_SHDW3 register is loaded into XMIN_ACTIVE register when shadow to active load occurs.
  [15:0] XMAX_SHDW3 — The value in the XMAX_SHDW3 register is loaded into XMAX_ACTIVE register when shadow to active load occurs.
0x428 CONTROLSS_G2_EPWM11_XREGSHDW2STS 32-bit
  [15:8] REENTRYDLY — Determines the blocking window after DEACTIVE flag is cleared in which setting of DEACTIVE flag is prevented from being set. 0 : No blocking 1 : Blocked until 1 PWMSYNCOUT event 2 : Blocked until 2 PWMSYNCOUT events . . 255 : Blocked until 127 PWMSYNCOUT events
  [1] MODE — 0 : DEACTIVE flag works in cycle by cycle mode. On every PWMSYNCOUT, set condition of DEACTIVE flag is evaluated. If the set condition is not present the flag is cleared. 1 : DEACTIVE flag works in one shot mode (hardware set) and software clear.
  [0] ENABLE — DE function enable 0 : Diode Emulation mode functionality is disabled. DEACTIVE flag is not set on a TRIPH_OR_TRIPL event. 1 : Diode Emulation mode functionality is enabled. DEACTIVE flag is set on a TRIPH_OR_TRIPL event. Note: ENABLE bit is cleared on a PWMTRIP event. Software has to re-enable this bit after PWMTRIP condition is serviced.
0x42C CONTROLSS_G2_EPWM11_RESERVED 32-bit
  [21:16] TRIPH — 000000 : Reserved000001 : Input-XBAR[0] is the source of TRIPH000010 : Input-XBAR[1] is the source of TRIPH..100000 : Input-XBAR[31] is the source of TRIPH100001 : CMPSSA0 is the source of TRIPH100010 : CMPSSA1 is the source of TRIPH..101010 : CMPSSA9 is the source of TRIPH101011 : Reserved..110000 : Reserved110001 : CMPSSB0 is the source of TRIPH110010 : CMPSSB1 is the source of TRIPH..111010 : CMPSSB9 is the source of TRIPH111011 : Reserved..111111 : ReservedNote: All the reserved encodings result in TRIPH being 0.
  [5:0] TRIPL — 000000 : Reserved000001 : Input-XBAR[0] is the source of TRIPL000010 : Input-XBAR[1] is the source of TRIPL..100000 : Input-XBAR[31] is the source of TRIPL100001 : CMPSSA0 is the source of TRIPL100010 : CMPSSA1 is the source of TRIPL..101010 : CMPSSA9 is the source of TRIPL101011 : Reserved..110000 : Reserved110001 : CMPSSB0 is the source of TRIPL110010 : CMPSSB1 is the source of TRIPL..111010 : CMPSSB9 is the source of TRIPL111011 : Reserved..111111 : ReservedNote: All the reserved encodings result in TRIPL being 0.
0x430 CONTROLSS_G2_EPWM11_XREGSHDW3STS 32-bit
  [16] TRIPENABLE — 0 : PWMTRIP does not bypass the diode emulation logic. 1 : PWMTRIP bypasses the diode emulation PWM generation logic (not complete bypass of module)
  [6] TRIPSELB — 0 : TRIPH 1 : TRIPL
  [5:4] PWMB — 00 : synchronized version of TRIPH or TRIPL signal as selected by the TRIPSELB 01 : synchronized and inverted version of TRIPH or TRIPL signal as selected by the TRIPSELB 10 : A constant 0 drives PWMB when DEACTIVE flag is set. 11 : A constant 1 drives PWMB when DEACTIVE flag is set.
  [2] TRIPSELA — 0 : TRIPH 1 : TRIPL
  [1:0] PWMA — 00 : synchronized version of TRIPH or TRIPL signal as selected by the TRIPSELA 01 : synchronized and inverted version of TRIPH or TRIPL signal as selected by the TRIPSELA 10 : A constant 0 drives PWMA when DEACTIVE flag is set. 11 : A constant 1 drives PWMA when DEACTIVE flag is set.
0x434 CONTROLSS_G2_EPWM11_RESERVED 32-bit ro
  [0] DEACTIVE — 0 : Diode emulation mode is not active 1 : Diode emulation mode is active
0x600 CONTROLSS_G2_EPWM11_XCMP1_ACTIVE 32-bit access not given
  [0] DEACTIVE — 0 : No effect. 1 : Forces DEACTIVE flag to 1. (access RW RRETURNS0S)
0x604 CONTROLSS_G2_EPWM11_XCMP2_ACTIVE 32-bit access not given
  [0] DEACTIVE — 0 : No effect. 1 : Clears DEACTIVE flag. (access RW RRETURNS0S)
0x608 CONTROLSS_G2_EPWM11_XCMP3_ACTIVE 32-bit ro
  [15:0] CNT — An 16-bit counter which monitors the frequency of diode mode trip events. When TripHorTripL is active: Increment CNT (increment INCSTEP on every EPWMxSYNC) When TripHorTripL is in-active: Decrement CNT (decrement DECSTEP on every EPWMxSYNC) If( CNT ' THRESHOLD) then generate DETRIP and clear the counter. If( (CNT - DECSTEP) < 0) then CNT = 0 If( (CNT + INCSTEP) '= 0xFFFF) then CNT = 0xFFFF Note : CNT is cleared when DECTL.ENABLE is 0 Note: DEMONTHRES == 0x0 should not generate trip as the DEMONTHRES and DEMONCNT registers have reset value of 0x0
0x60C CONTROLSS_G2_EPWM11_XCMP4_ACTIVE 32-bit
  [0] ENABLE — Enable bit for DE Mode Monitor counter function. 0: DE Mode Monitor counter function is disabled 1: DE Mode Monitor counter function is enabled
0x610 CONTROLSS_G2_EPWM11_XCMP5_ACTIVE 32-bit
  [23:16] DECSTEP — Defines the decrement step of DEMONCNT.CNT counter.
  [7:0] INCSTEP — Defines the increment step of DEMONCNT.CNT counter.
0x614 CONTROLSS_G2_EPWM11_XCMP6_ACTIVE 32-bit
  [15:0] THRESHOLD — Defines the threshold of DE monitor counter.
0x618 CONTROLSS_G2_EPWM11_XCMP7_ACTIVE 32-bit
  [24] POLSELB — Select signal for the AND OR logic of BLOCKB (output of SELBLOCKB mux) and PWMB signals 0 : Select BLOCKB is inverted and ANDed with PWMB. 1 : Select BLOCKB is Ored with PWMB.
  [23:20] SELB — PWMB min dead band reference 0x0 : DEPWMB 0x1 : Output 1 from PWM output XBAR 0x2 : Output 2 from PWM output XBAR . . 0xf : Output 15 from PWM output XBAR
  [19] SELBLOCKB — 0 : Select BLOCKB as the blocking signal on PWMB. 1 : Select BLOCKA as the blocking signal on PWMB.
  [18] INVERTB — 0 : No inversion on the selected reference signal which is used in the min deadband logic on PWMB. 1 : Invert the selected reference signal which is used in the min deadband logic on PWMB.
  [16] ENABLEB — 0 : Minimum dead band logic is disabled 1 : Minimum dead band logic is enabled
  [8] POLSELA — Select signal for the AND OR logic of BLOCKA (output of SELBLOCKA mux) and PWMA signals 0 : Select BLOCKA is inverted and ANDed with PWMA. 1 : Select BLOCKA is Ored with PWMA.
  [7:4] SELA — PWMA min dead band reference 0x0 : DEPWMA 0x1 : Output 1 from PWM output XBAR 0x2 : Output 2 from PWM output XBAR . . 0xf : Output 15 from PWM output XBAR
  [3] SELBLOCKA — 0 : Select BLOCKA as the blocking signal on PWMA. 1 : Select BLOCKB as the blocking signal on PWMB.
  [2] INVERTA — 0 : No inversion on the selected reference signal which is used in the min deadband logic on PWMA. 1 : Invert the selected reference signal which is used in the min deadband logic on PWMA.
  [0] ENABLEA — 0 : Minimum dead band logic is disabled 1 : Minimum dead band logic is enabled
0x61C CONTROLSS_G2_EPWM11_XCMP8_ACTIVE 32-bit
  [31:16] DELAYB — Minimum dead band delay on PWMB in terms of SYSCLK cycles. For delay value of 0, user should configure MINDBCFG[ENABLEA/B] = '0'. If MINDBCFG[ENABLEA/B] = '1' and MINDBDLY[DELAYA/B]='0' then delay is '1' cycle is applied.
  [15:0] DELAYA — Minimum dead band delay on PWMA in terms of SYSCLK cycles. For delay value of 0, user should configure MINDBCFG[ENABLEA/B] = '0'. If MINDBCFG[ENABLEA/B] = '1' and MINDBDLY[DELAYA/B]='0' then delay is '1' cycle is applied.
0x620 CONTROLSS_G2_EPWM11_XTBPRD_ACTIVE 32-bit
  [n+16] LUTDEC{n} (n=0..7) — 0 : Force 0 1 : Force 1
  [7:4] SELXBAR — Selects one of the 16 outputs of ICSSXBAR to feed into IN3 of LUTA
  [0] BYPASS — 1 : Bypass LUT logic on PWMA 0 : PWMA driven by LUTA
0x624 CONTROLSS_G2_EPWM11_RESERVED 32-bit
  [n+16] LUTDEC{n} (n=0..7) — 0 : Force 0 1 : Force 1
  [7:4] SELXBAR — Selects one of the 16 outputs of ICSSXBAR to feed into IN3 of LUTB
  [0] BYPASS — 1 : Bypass LUT logic on PWMB 0 : PWMB driven by LUTB
